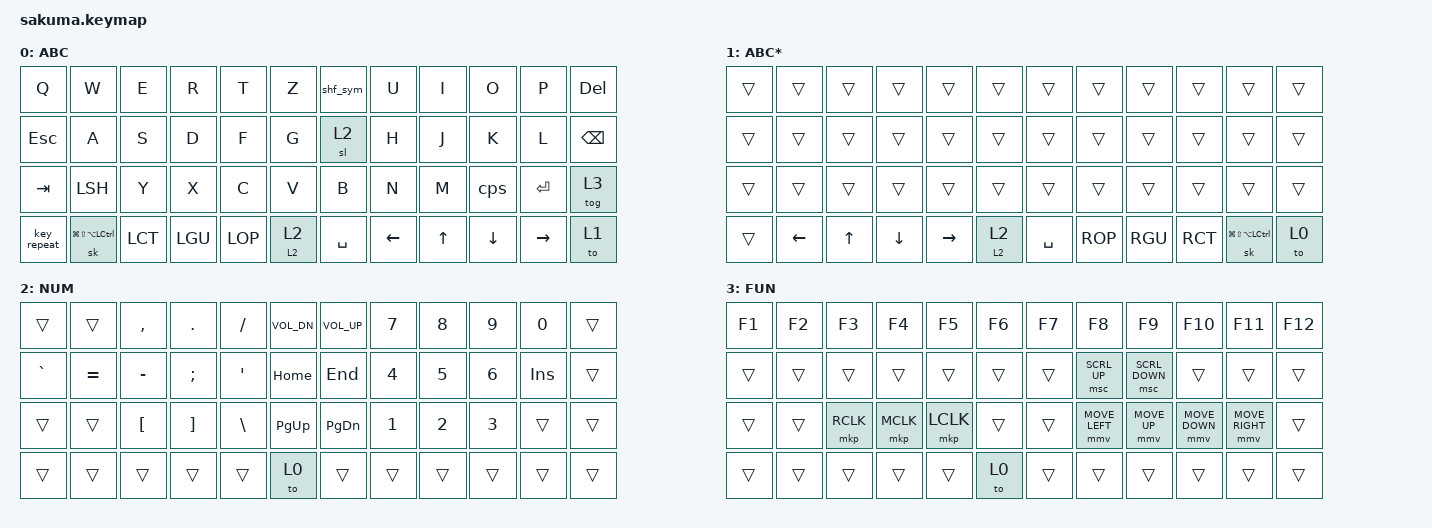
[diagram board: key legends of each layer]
#include <behaviors.dtsi>
#include <dt-bindings/zmk/keys.h>
// #include <dt-bindings/zmk/bt.h>

&caps_word { continue-list = <MINUS UNDERSCORE BSPC DEL LEFT RIGHT DOT COMMA SEMI SLASH>; };
&sk { release-after-ms = <2000>; lazy; };
&sl { release-after-ms = <1500>; /delete-property/ quick-release; };


#define xxxx &none
#define ____ &trans
#define ks(l) &ksk l l 
#define LCT ks(LCTRL)
#define LGU ks(LGUI)
#define LOP ks(LALT)
#define LSH ks(LSHFT)
#define RCT ks(RCTRL)
#define RGU ks(RGUI)
#define ROP ks(RALT)
#define RSH ks(RSHFT)
#define LEADR &sk LG(LS(LA(LCTRL)))
#define REP &key_repeat
#define VOLDN &kp C_VOL_DN
#define VOLUP &kp C_VOL_UP

#define SLN &sl 2
#define NUM &motg 2 2
#define FUN &motg 3 3
#define MOU &tog 3
#define RST &to 0

#define ZMK_MOUSE_DEFAULT_MOVE_VAL 7000  // 600
#define ZMK_MOUSE_DEFAULT_SCRL_VAL 8000  // 10
#include <dt-bindings/zmk/pointing.h>
&mmv {
  acceleration-exponent = <1>;      // 1
  time-to-max-speed-ms = <700>;    // 40
};
&msc {
  acceleration-exponent = <0>;      // 0
  time-to-max-speed-ms = <300>;   // 500
};

/ { 
    macros {
        shf_sym: shift_symbols { compatible = "zmk,behavior-macro"; #binding-cells = <0>; wait-ms = <5>; tap-ms = <15>;
            bindings = <&macro_tap &sk LSHFT SLN>; };
    };

    behaviors {
        ksk: kp_sk        { compatible = "zmk,behavior-hold-tap";  #binding-cells = <2>; flavor = "balanced"; tapping-term-ms = <200>; bindings = <&kp>, <&sk>; }; 
        motg: mo_tog      { compatible = "zmk,behavior-hold-tap";  #binding-cells = <2>; flavor = "balanced"; tapping-term-ms = <200>; bindings = <&mo>, <&tog>; }; 
//        blt: bluetoot     { compatible = "zmk,behavior-mod-morph"; #binding-cells = <0>; bindings = <&bt BT_NXT>, <&bt BT_CLR>; mods = <MOD_RALT>; };
        cps: caps_wrd     { compatible = "zmk,behavior-mod-morph"; #binding-cells = <0>; bindings = <&caps_word>, <&kp CAPS>; mods = <MOD_LSFT>; };
    };
  
    keymap {
        compatible = "zmk,keymap";
        abc {
            display-name = "ABC";
            bindings = <
            //  1       2       3       4       5       6       7           8           9           10          11          12 
                &kp Q   &kp W   &kp E   &kp R   &kp T   &kp Z   &shf_sym    &kp U       &kp I       &kp O       &kp P       &kp DEL 
                &kp ESC &kp A   &kp S   &kp D   &kp F   &kp G   SLN         &kp H       &kp J       &kp K       &kp L       &kp BSPC 
                &kp TAB LSH     &kp Y   &kp X   &kp C   &kp V   &kp B       &kp N       &kp M       &cps        &kp ENTER   MOU 
                REP     LEADR   LCT     LGU     LOP     NUM     &kp SPACE   &kp LEFT    &kp UP      &kp DOWN    &kp RIGHT   &to 1 
            >; 
        };

        swap {
            display-name = "ABC*";
            bindings = <
            //  1       2           3       4           5           6       7           8       9       10      11      12 
                ____    ____        ____    ____        ____        ____    ____        ____    ____    ____    ____    ____ 
                ____    ____        ____    ____        ____        ____    ____        ____    ____    ____    ____    ____ 
                ____    ____        ____    ____        ____        ____    ____        ____    ____    ____    ____    ____ 
                ____    &kp LEFT    &kp UP  &kp DOWN    &kp RIGHT   NUM     &kp SPACE   ROP     RGU     RCT     LEADR   &to 0 
            >; 
        };

        num {
            display-name = "NUM";
            bindings = <
            //  1           2           3           4           5           6           7           8       9       10      11      12 
                ____        ____        &kp COMMA   &kp DOT     &kp SLASH   VOLDN       VOLUP       &kp N7  &kp N8  &kp N9  &kp N0  ____ 
                &kp GRAVE   &kp EQUAL   &kp MINUS   &kp SEMI    &kp SQT     &kp HOME    &kp END     &kp N4  &kp N5  &kp N6  &kp INS ____ 
                ____        ____        &kp LBKT    &kp RBKT    &kp BSLH    &kp PG_UP   &kp PG_DN   &kp N1  &kp N2  &kp N3  ____    ____ 
                ____        ____        ____        ____        ____        RST         ____        ____    ____    ____    ____    ____ 
            >; 
        };

        fun {
            display-name = "FUN";
            bindings = <
            //  1       2       3           4           5           6       7       8               9               10              11              12 
                &kp F1  &kp F2  &kp F3      &kp F4      &kp F5      &kp F6  &kp F7  &kp F8          &kp F9          &kp F10         &kp F11         &kp F12 
                ____    ____    ____        ____        ____        ____    ____    &msc SCRL_UP    &msc SCRL_DOWN  ____            ____            ____ 
                ____    ____    &mkp RCLK   &mkp MCLK   &mkp LCLK   ____    ____    &mmv MOVE_LEFT  &mmv MOVE_UP    &mmv MOVE_DOWN  &mmv MOVE_RIGHT ____ 
                ____    ____    ____        ____        ____        RST     ____    ____            ____            ____            ____            ____ 
            >; 
        }; 
    }; 
};
